# M461 register map
File version: 2.0.2.2
Registers are 32-bit, read-write, reset 0x0 unless marked. A register's access mark holds for its fields unless they carry their own. Offsets are from the block's base; [hi:lo] are bit positions; {n}, {i} and the like mark numbered series.

## PK — Port K
Base 0x402C0900
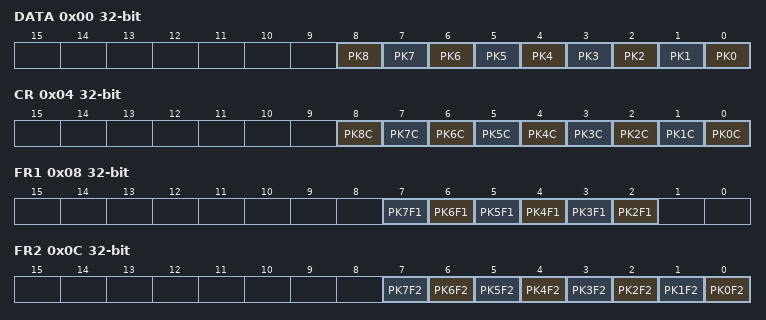
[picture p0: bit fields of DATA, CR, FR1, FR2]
0x00 DATA — Port K Data Register
  [n] PK{n} (n=0..8)
0x04 CR — Port K Output Control Register
  [n] PK{n}C (n=0..8)
0x08 FR1 — Port K Function Register 1
  [n] PK{n}F1 (n=2..7)
0x0C FR2 — Port K Function Register 2
  [n] PK{n}F2 (n=0..7)
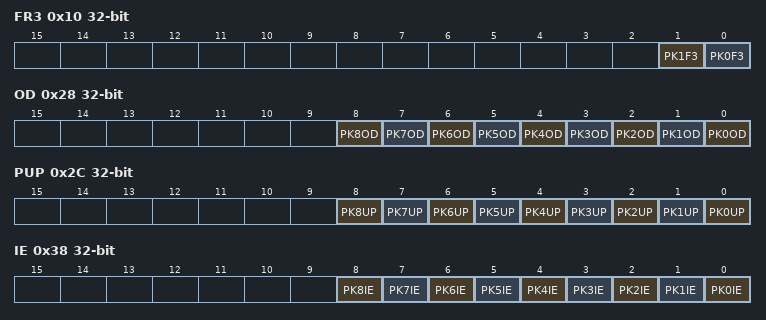
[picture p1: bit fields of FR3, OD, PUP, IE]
0x10 FR3 — Port K Function Register 3
  [1] PK1F3, [0] PK0F3
0x28 OD — Port K Open Drain Control Register
  [n] PK{n}OD (n=0..8)
0x2C PUP — Port K Pull-up Control Register
  [n] PK{n}UP (n=0..8)
0x38 IE — Port K Input Control Register
  [n] PK{n}IE (n=0..8)

## MT0 — 16-bit Multi-Purpose Timer (MPT-TMR_IGBT)
Base 0x402C7000
Same registers: MT1 0x402C7100
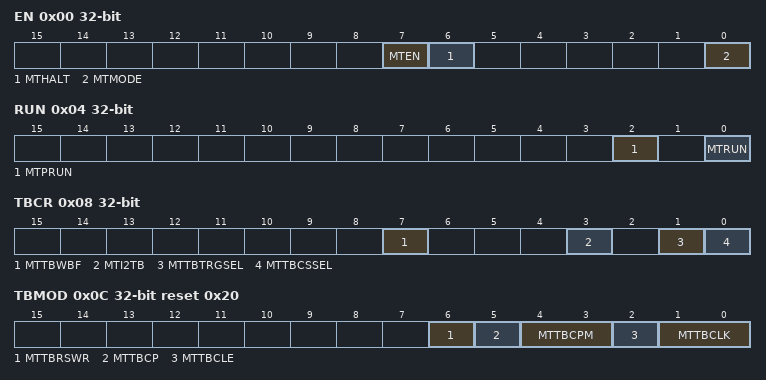
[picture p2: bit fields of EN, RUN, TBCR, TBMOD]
0x00 EN — MPT Enable Register
  [7] MTEN, [6] MTHALT, [0] MTMODE
0x04 RUN — MPT RUN Register
  [2] MTPRUN, [0] MTRUN
0x08 TBCR — MPT Control Register
  [7] MTTBWBF, [3] MTI2TB, [1] MTTBTRGSEL, [0] MTTBCSSEL
0x0C TBMOD reset 0x20 — MPT Mode Register
  [6] MTTBRSWR, [5] MTTBCP wo, [4:3] MTTBCPM, [2] MTTBCLE, [1:0] MTTBCLK
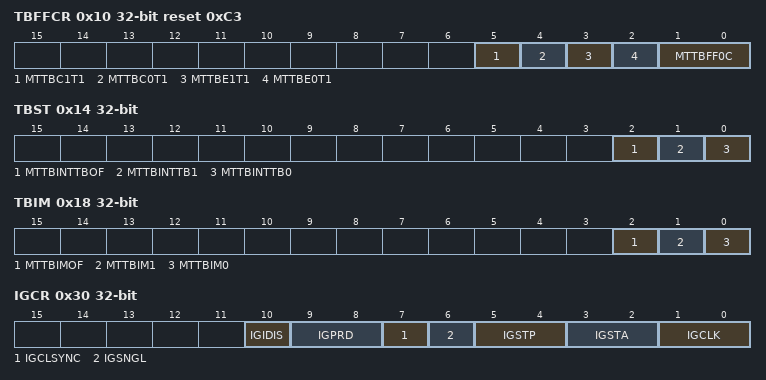
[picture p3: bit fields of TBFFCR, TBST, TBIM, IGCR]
0x10 TBFFCR reset 0xC3 — MPT Flip-Flop Control Register
  [5] MTTBC1T1, [4] MTTBC0T1, [3] MTTBE1T1, [2] MTTBE0T1, [1:0] MTTBFF0C
0x14 TBST ro — MPT Status Register
  [2] MTTBINTTBOF, [1] MTTBINTTB1, [0] MTTBINTTB0
0x18 TBIM — MPT Interrupt Mask Register
  [2] MTTBIMOF, [1] MTTBIM1, [0] MTTBIM0
0x1C TBUC ro — MPT Read Capture Register
  [15:0] MTUC
0x20 RG0 — MPT RG0 Timer Register
  [15:0] MTRG0
0x24 RG1 — MPT RG1 Timer Register
  [15:0] MTRG1
0x28 CP0 ro — MPT CP0 Capture Register
  [15:0] MTCP0
0x2C CP1 ro — MPT CP1 Capture Register
  [15:0] MTCP1
0x30 IGCR — IGBT Control Register
  [10] IGIDIS, [9:8] IGPRD, [7] IGCLSYNC, [6] IGSNGL, [5:4] IGSTP, [3:2] IGSTA, [1:0] IGCLK
0x34 IGRESTA wo — IGBT Timer Restart Register
  [0] IGRESTA
0x38 IGST ro — IGBT Timer Status Register
  [0] IGST
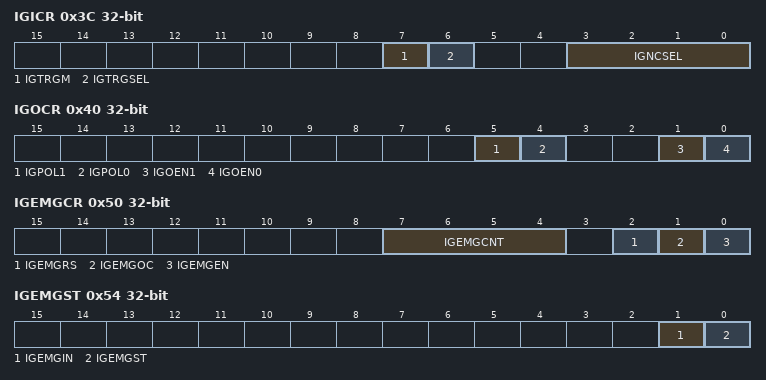
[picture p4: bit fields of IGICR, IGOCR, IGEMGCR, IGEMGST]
0x3C IGICR — IGBT Input Control Register
  [7] IGTRGM, [6] IGTRGSEL, [3:0] IGNCSEL
0x40 IGOCR — IGBT Output Control Register
  [5] IGPOL1, [4] IGPOL0, [1] IGOEN1, [0] IGOEN0
{0x3C+4i} IGRG{i} (i=2..4) — IGBT RG{i} Timer Register
  [15:0] IGRG{i}
0x50 IGEMGCR — IGBT EMG Control Register
  [7:4] IGEMGCNT, [2] IGEMGRS wo, [1] IGEMGOC, [0] IGEMGEN
0x54 IGEMGST ro — IGBT EMG Status Register
  [1] IGEMGIN, [0] IGEMGST
0x58 IGTRG — IGBT Trigger Status Register
  [15:0] IGTRG

## OFD — Oscillation Frequency Detector (OFD)
Base 0x402F1000
0x00 CR1 reset 0x6 — OFD Control Register 1
  [7:0] OFDWEN
0x04 CR2 — OFD Control Register 2
  [7:0] OFDEN
0x08 MN0 — OFD Lower Detection Frequency Setting Register0
  [8:0] OFDMN0
0x0C MN1 — OFD Lower Detection Frequency Setting Register1
  [8:0] OFDMN1
0x10 MX0 — OFD Higher Detection Frequency Setting Register0
  [8:0] OFDMX0
0x14 MX1 — OFD Higher Detection Frequency Setting Register1
  [8:0] OFDMX1
0x18 RST reset 0x1 — OFD Reset Enable Control Register
  [0] OFDRSTEN
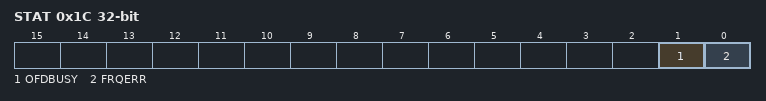
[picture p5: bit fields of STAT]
0x1C STAT ro — OFD Status Register
  [1] OFDBUSY, [0] FRQERR
0x20 MON reset 0x1 — OFD External high frequency oscillaion clock monitor register
  [0] OFDMON

## WD — Watchdog Timer (WD)
Base 0x402F2000
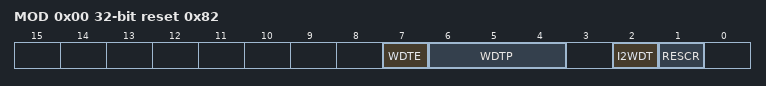
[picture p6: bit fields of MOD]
0x00 MOD reset 0x82 — WD Mode Register
  [7] WDTE, [6:4] WDTP, [2] I2WDT, [1] RESCR
0x04 CR wo (reset mask 0xFFFFFF00) — WD Control Register
  [7:0] WDCR

## RTC — Real Time Clock (RTC)
Base 0x403CC000
0x00 SECR 8-bit (reset mask 0x80) — RTC Sec setting register
  [6:0] SE
0x01 MINR 8-bit (reset mask 0x80) — RTC Min settging register
  [6:0] MI
0x02 HOURR 8-bit (reset mask 0xC0) — RTC Hour setting register
  [5:0] HO
0x04 DAYR 8-bit (reset mask 0xF8) — RTC Day setting register
  [2:0] WE
0x05 DATER 8-bit (reset mask 0xC0) — RTC Date setting register
  [5:0] DA
0x06 MONTHR 8-bit (reset mask 0xE0) — RTC Month settging register PAGE0
  [4:0] MO
0x07 YEARR_A 8-bit reset not defined — RTC Year setting register PAGE0
  [7:0] YE
0x07 YEARR_B 8-bit (reset mask 0xFC) (RTC_YEARR view) — RTC Leap year register PAGE1
  [1:0] LEAP
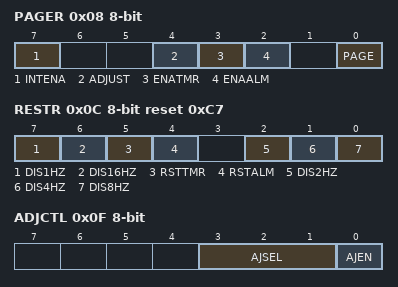
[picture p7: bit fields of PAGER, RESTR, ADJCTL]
0x08 PAGER 8-bit (reset mask 0xF3) — RTC Page register
  [7] INTENA, [4] ADJUST, [3] ENATMR, [2] ENAALM, [0] PAGE
0x0C RESTR 8-bit reset 0xC7 — RTC Reset register
  [7] DIS1HZ, [6] DIS16HZ, [5] RSTTMR, [4] RSTALM, [2] DIS2HZ, [1] DIS4HZ, [0] DIS8HZ
0x0E PROTECT 8-bit reset 0xC1 — RTC protect register
0x0F ADJCTL 8-bit (reset mask 0xF0) — RTC clock adjust control register
  [3:1] AJSEL, [0] AJEN
0x10 ADJDAT 16-bit (reset mask 0xFE00) — RTC clock adjust data register
  [8:0] ADJDAT
